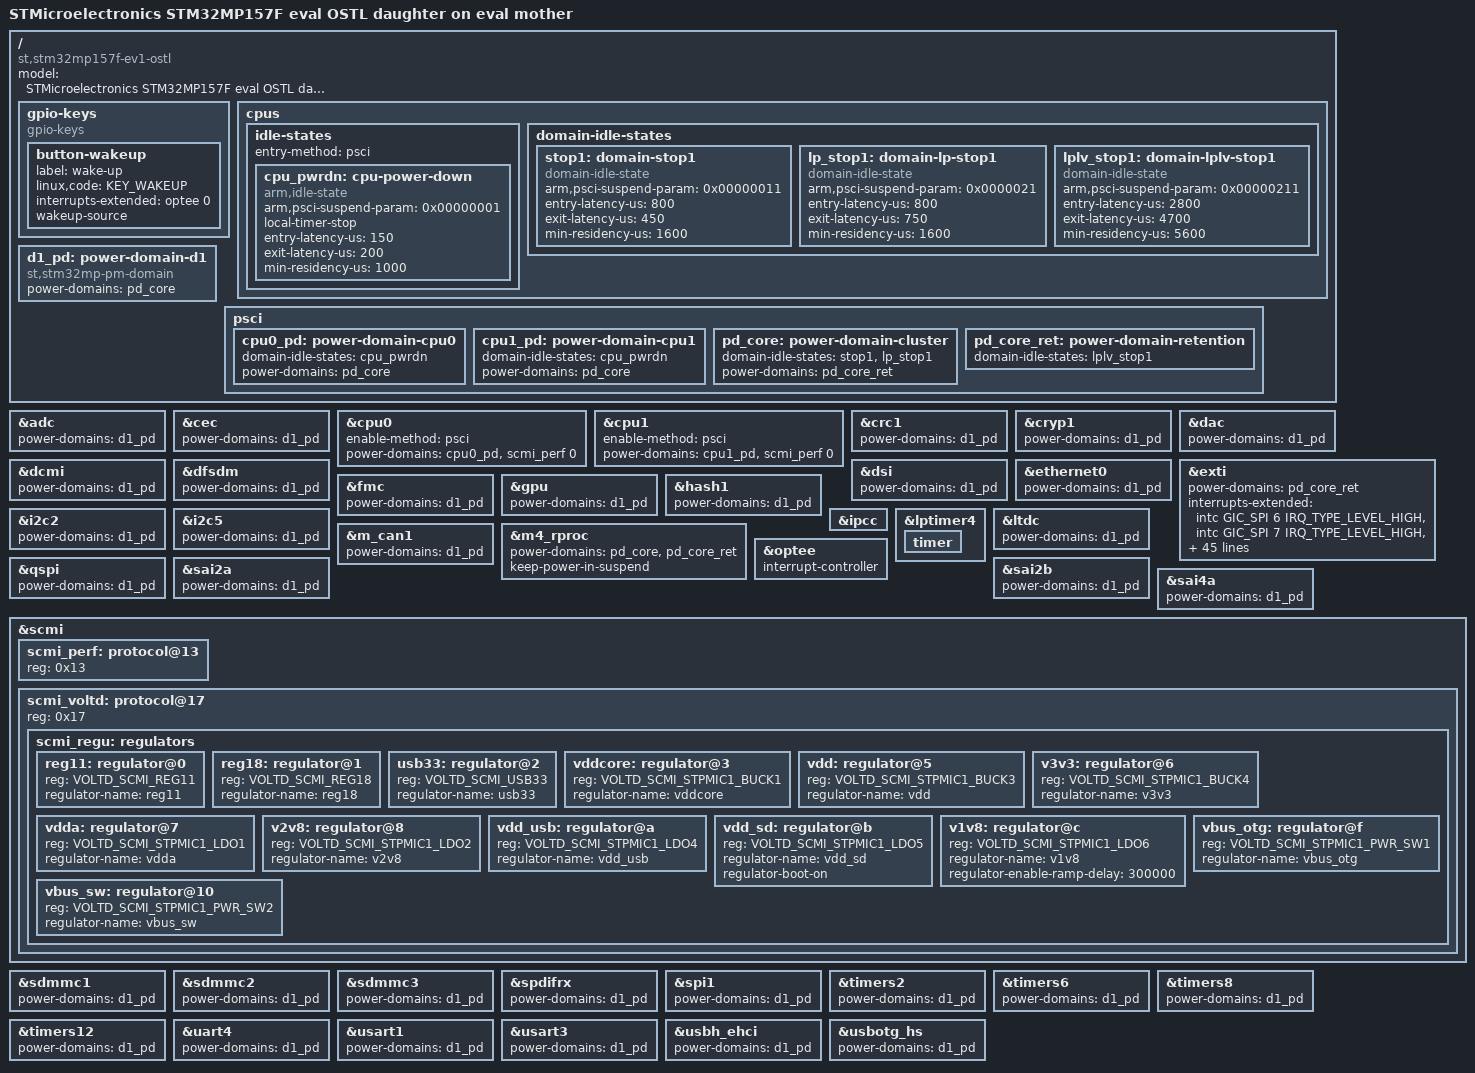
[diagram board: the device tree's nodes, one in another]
// SPDX-License-Identifier: (GPL-2.0-only OR BSD-3-Clause)
/*
 * Copyright (C) STMicroelectronics 2025 - All Rights Reserved
 * Author: Alexandre Torgue <alexandre.torgue@st.com> for STMicroelectronics.
 * Author: Pascal Paillet <p.paillet@st.com> for STMicroelectronics.
 */
/dts-v1/;

#include "stm32mp157f-ev1.dts"
#include <dt-bindings/input/input.h>
#include <dt-bindings/regulator/st,stm32mp15-regulator.h>

/* Delete PWR IRQs are handled by OPTEE */
/delete-node/ &pwr_irq;
/* Delete PWR regulators now be provided by SCMI */
/delete-node/ &pwr_regulators;
/* Delete I2C4 + PMIC now be provided by SCMI */
/delete-node/ &i2c4;
/* Opp table is provided by SCMI performance */
/delete-node/ &cpu0_opp_table;

/ {
	model = "STMicroelectronics STM32MP157F eval OSTL daughter on eval mother";
	compatible = "st,stm32mp157f-ev1-ostl", "st,stm32mp157f-ev1", "st,stm32mp157f-ed1", "st,stm32mp157";

	/* ST PM domain are replaced by PSCI ones */
	/delete-node/ pm_domain;

	gpio-keys {
		compatible = "gpio-keys";

		button-wakeup {
			label = "wake-up";
			linux,code = <KEY_WAKEUP>;
			interrupts-extended = <&optee 0>;
			wakeup-source;
		};
	};

	cpus {
		idle-states {
			entry-method = "psci";

			cpu_pwrdn: cpu-power-down {
				compatible = "arm,idle-state";
				arm,psci-suspend-param = <0x00000001>;
				local-timer-stop;
				/* TODO: update latency values */
				entry-latency-us = <150>;
				exit-latency-us = <200>;
				min-residency-us = <1000>;
			};
		};

		domain-idle-states {
			stop1: domain-stop1 {
				compatible = "domain-idle-state";
				arm,psci-suspend-param = <0x00000011>;
				/* TODO: update latency values */
				entry-latency-us = <800>;
				exit-latency-us = <450>;
				min-residency-us = <1600>;
			};

			lp_stop1: domain-lp-stop1 {
				compatible = "domain-idle-state";
				arm,psci-suspend-param = <0x0000021>;
				/* TODO: update latency values */
				entry-latency-us = <800>;
				exit-latency-us = <750>;
				min-residency-us = <1600>;
			};

			lplv_stop1: domain-lplv-stop1 {
				compatible = "domain-idle-state";
				arm,psci-suspend-param = <0x00000211>;
				/* TODO: update latency values */
				entry-latency-us = <2800>;
				exit-latency-us = <4700>;
				min-residency-us = <5600>;
			};
		};
	};

	d1_pd: power-domain-d1 {
		compatible = "st,stm32mp-pm-domain";
		#power-domain-cells = <0>;
		power-domains = <&pd_core>;
	};

	psci {
		cpu0_pd: power-domain-cpu0 {
			#power-domain-cells = <0>;
			domain-idle-states = <&cpu_pwrdn>;
			power-domains = <&pd_core>;
		};

		cpu1_pd: power-domain-cpu1 {
			#power-domain-cells = <0>;
			domain-idle-states = <&cpu_pwrdn>;
			power-domains = <&pd_core>;
		};

		pd_core: power-domain-cluster {
			#power-domain-cells = <0>;
			domain-idle-states = <&stop1>, <&lp_stop1>;
			power-domains = <&pd_core_ret>;
		};

		pd_core_ret: power-domain-retention {
			#power-domain-cells = <0>;
			domain-idle-states = <&lplv_stop1>;
		};
	};
};

&adc {
	power-domains = <&d1_pd>;
};

&cec {
	power-domains = <&d1_pd>;
};

&cpu0 {
	/delete-property/operating-points-v2;
	/delete-property/clock-names;
	/delete-property/clocks;
	enable-method = "psci";
	power-domains = <&cpu0_pd>, <&scmi_perf 0>;
	power-domain-names = "psci", "perf";
};

&cpu1 {
	/delete-property/operating-points-v2;
	/delete-property/clock-names;
	/delete-property/clocks;
	enable-method = "psci";
	power-domains = <&cpu1_pd>, <&scmi_perf 0>;
	power-domain-names = "psci", "perf";
};

&crc1 {
	power-domains = <&d1_pd>;
};

&cryp1 {
	power-domains = <&d1_pd>;
};

&dac {
	power-domains = <&d1_pd>;
};

&dcmi {
	power-domains = <&d1_pd>;
};

&dfsdm {
	power-domains = <&d1_pd>;
};

&dsi {
	power-domains = <&d1_pd>;
};

&ethernet0 {
	power-domains = <&d1_pd>;
};

/* Redefine EXTI interrupts list as PWR IRQ are handled by OPTEE */
&exti {
	/delete-property/wakeup-parent;
	power-domains = <&pd_core_ret>;
	interrupts-extended =
		<&intc GIC_SPI 6   IRQ_TYPE_LEVEL_HIGH>,	/* EXTI_0 */
		<&intc GIC_SPI 7   IRQ_TYPE_LEVEL_HIGH>,
		<&intc GIC_SPI 8   IRQ_TYPE_LEVEL_HIGH>,
		<&intc GIC_SPI 9   IRQ_TYPE_LEVEL_HIGH>,
		<&intc GIC_SPI 10  IRQ_TYPE_LEVEL_HIGH>,
		<&intc GIC_SPI 23  IRQ_TYPE_LEVEL_HIGH>,
		<&intc GIC_SPI 64  IRQ_TYPE_LEVEL_HIGH>,
		<&intc GIC_SPI 65  IRQ_TYPE_LEVEL_HIGH>,
		<&intc GIC_SPI 66  IRQ_TYPE_LEVEL_HIGH>,
		<&intc GIC_SPI 67  IRQ_TYPE_LEVEL_HIGH>,
		<&intc GIC_SPI 40  IRQ_TYPE_LEVEL_HIGH>,	/* EXTI_10 */
		<&intc GIC_SPI 42  IRQ_TYPE_LEVEL_HIGH>,
		<&intc GIC_SPI 76  IRQ_TYPE_LEVEL_HIGH>,
		<&intc GIC_SPI 77  IRQ_TYPE_LEVEL_HIGH>,
		<&intc GIC_SPI 121 IRQ_TYPE_LEVEL_HIGH>,
		<&intc GIC_SPI 127 IRQ_TYPE_LEVEL_HIGH>,
		<&intc GIC_SPI 1   IRQ_TYPE_LEVEL_HIGH>,
		<0>,
		<0>,
		<&intc GIC_SPI 3   IRQ_TYPE_LEVEL_HIGH>,
		<0>,						/* EXTI_20 */
		<&intc GIC_SPI 31  IRQ_TYPE_LEVEL_HIGH>,
		<&intc GIC_SPI 33  IRQ_TYPE_LEVEL_HIGH>,
		<&intc GIC_SPI 72  IRQ_TYPE_LEVEL_HIGH>,
		<&intc GIC_SPI 95  IRQ_TYPE_LEVEL_HIGH>,
		<&intc GIC_SPI 107 IRQ_TYPE_LEVEL_HIGH>,
		<&intc GIC_SPI 37  IRQ_TYPE_LEVEL_HIGH>,
		<&intc GIC_SPI 38  IRQ_TYPE_LEVEL_HIGH>,
		<&intc GIC_SPI 39  IRQ_TYPE_LEVEL_HIGH>,
		<&intc GIC_SPI 71  IRQ_TYPE_LEVEL_HIGH>,
		<&intc GIC_SPI 52  IRQ_TYPE_LEVEL_HIGH>,	/* EXTI_30 */
		<&intc GIC_SPI 53  IRQ_TYPE_LEVEL_HIGH>,
		<&intc GIC_SPI 82  IRQ_TYPE_LEVEL_HIGH>,
		<&intc GIC_SPI 83  IRQ_TYPE_LEVEL_HIGH>,
		<0>,
		<0>,
		<0>,
		<0>,
		<0>,
		<0>,
		<0>,						/* EXTI_40 */
		<0>,
		<0>,
		<&intc GIC_SPI 75  IRQ_TYPE_LEVEL_HIGH>,
		<&intc GIC_SPI 98  IRQ_TYPE_LEVEL_HIGH>,
		<0>,
		<0>,
		<&intc GIC_SPI 93  IRQ_TYPE_LEVEL_HIGH>,
		<&intc GIC_SPI 138 IRQ_TYPE_LEVEL_HIGH>,
		<0>,
		<&intc GIC_SPI 139 IRQ_TYPE_LEVEL_HIGH>,	/* EXTI_50 */
		<0>,
		<&intc GIC_SPI 140 IRQ_TYPE_LEVEL_HIGH>,
		<&intc GIC_SPI 141 IRQ_TYPE_LEVEL_HIGH>,
		<&intc GIC_SPI 135 IRQ_TYPE_LEVEL_HIGH>,
		<0>,
		<0>,
		<0>,
		<0>,
		<0>,
		<0>,						/* EXTI_60 */
		<&intc GIC_SPI 100 IRQ_TYPE_LEVEL_HIGH>,
		<0>,
		<0>,
		<0>,
		<&intc GIC_SPI 144 IRQ_TYPE_LEVEL_HIGH>,
		<0>,
		<0>,
		<&intc GIC_SPI 143 IRQ_TYPE_LEVEL_HIGH>,
		<&intc GIC_SPI 94  IRQ_TYPE_LEVEL_HIGH>,
		<&intc GIC_SPI 62  IRQ_TYPE_LEVEL_HIGH>,	/* EXTI_70 */
		<0>,
		<0>,
		<&intc GIC_SPI 129 IRQ_TYPE_LEVEL_HIGH>;
};

&fmc {
	power-domains = <&d1_pd>;
};

&gpu {
	power-domains = <&d1_pd>;
};

&hash1 {
	power-domains = <&d1_pd>;
};

&i2c2 {
	power-domains = <&d1_pd>;
};

&i2c5 {
	power-domains = <&d1_pd>;
};

&ipcc {
	/delete-property/ power-domains;
};

/* use lptimer with tick broadcast for suspend mode */
&lptimer4 {
	/delete-property/ power-domains;

	status = "okay";

	timer {
		status = "okay";
	};
};

&ltdc {
	power-domains = <&d1_pd>;
};

&m_can1 {
	power-domains = <&d1_pd>;
};

&m4_rproc {
	power-domains = <&pd_core>, <&pd_core_ret>;
	power-domain-names = "default", "sleep";
	keep-power-in-suspend;
};

&optee {
	interrupt-controller;
	#interrupt-cells = <1>;
};

&qspi {
	power-domains = <&d1_pd>;
};

&sai2a {
	power-domains = <&d1_pd>;
};

&sai2b {
	power-domains = <&d1_pd>;
};

&sai4a {
	power-domains = <&d1_pd>;
};

&scmi {
	scmi_perf: protocol@13 {
		reg = <0x13>;
		#power-domain-cells = <1>;
	};

	scmi_voltd: protocol@17 {
		reg = <0x17>;

		scmi_regu: regulators {
			#address-cells = <1>;
			#size-cells = <0>;

			reg11: regulator@0 {
				reg = <VOLTD_SCMI_REG11>;
				regulator-name = "reg11";
			};

			reg18: regulator@1 {
				reg = <VOLTD_SCMI_REG18>;
				regulator-name = "reg18";
			};

			usb33: regulator@2 {
				reg = <VOLTD_SCMI_USB33>;
				regulator-name = "usb33";
			};

			vddcore: regulator@3 {
				reg = <VOLTD_SCMI_STPMIC1_BUCK1>;
				regulator-name = "vddcore";
			};

			vdd: regulator@5 {
				reg = <VOLTD_SCMI_STPMIC1_BUCK3>;
				regulator-name = "vdd";
			};

			v3v3: regulator@6 {
				reg = <VOLTD_SCMI_STPMIC1_BUCK4>;
				regulator-name = "v3v3";
			};

			vdda: regulator@7 {
				reg = <VOLTD_SCMI_STPMIC1_LDO1>;
				regulator-name = "vdda";
			};

			v2v8: regulator@8 {
				reg = <VOLTD_SCMI_STPMIC1_LDO2>;
				regulator-name = "v2v8";
			};

			vdd_usb: regulator@a {
				reg = <VOLTD_SCMI_STPMIC1_LDO4>;
				regulator-name = "vdd_usb";
			};

			vdd_sd: regulator@b {
				reg = <VOLTD_SCMI_STPMIC1_LDO5>;
				regulator-name = "vdd_sd";
				regulator-boot-on;
			};

			v1v8: regulator@c {
				reg = <VOLTD_SCMI_STPMIC1_LDO6>;
				regulator-name = "v1v8";
				regulator-enable-ramp-delay = <300000>;
			};

			vbus_otg: regulator@f {
				reg = <VOLTD_SCMI_STPMIC1_PWR_SW1>;
				regulator-name = "vbus_otg";
			};

			vbus_sw: regulator@10 {
				reg = <VOLTD_SCMI_STPMIC1_PWR_SW2>;
				regulator-name = "vbus_sw";
			};
		};
	};
};

&sdmmc1 {
	power-domains = <&d1_pd>;
};

&sdmmc2 {
	power-domains = <&d1_pd>;
};

&sdmmc3 {
	power-domains = <&d1_pd>;
};

&spdifrx {
	power-domains = <&d1_pd>;
};

&spi1 {
	power-domains = <&d1_pd>;
};

&timers2 {
	power-domains = <&d1_pd>;
};

&timers6 {
	power-domains = <&d1_pd>;
};

&timers8 {
	power-domains = <&d1_pd>;
};

&timers12 {
	power-domains = <&d1_pd>;
};

&uart4 {
	power-domains = <&d1_pd>;
};

&usart1 {
	power-domains = <&d1_pd>;
};

&usart3 {
	power-domains = <&d1_pd>;
};

&usbh_ehci {
	power-domains = <&d1_pd>;
};

&usbotg_hs {
	power-domains = <&d1_pd>;
};
